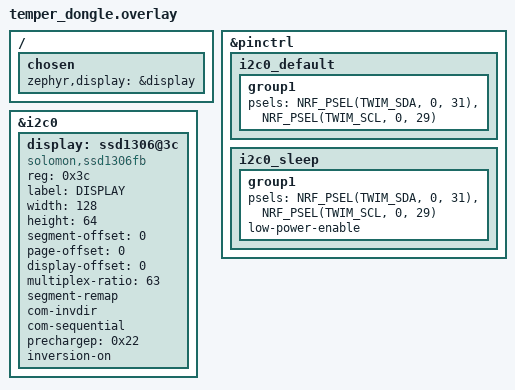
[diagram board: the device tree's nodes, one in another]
/*
 * Copyright (c) 2020 Pete Johanson
 *
 * SPDX-License-Identifier: MIT
 */

#include "temper.dtsi"

&pinctrl {
    i2c0_default: i2c0_default {
        group1 {
            psels = <NRF_PSEL(TWIM_SDA, 0, 31)>,
                    <NRF_PSEL(TWIM_SCL, 0, 29)>;
        };
    };

    i2c0_sleep: i2c0_sleep {
        group1 {
            psels = <NRF_PSEL(TWIM_SDA, 0, 31)>,
                    <NRF_PSEL(TWIM_SCL, 0, 29)>;
            low-power-enable;
        };
    };
};

&i2c0 {
    status = "okay";

    display: ssd1306@3c {
        compatible = "solomon,ssd1306fb";
        reg = <0x3c>;
        label = "DISPLAY";
        width = <128>;
        height = <64>;
        segment-offset = <0>;
        page-offset = <0>;
        display-offset = <0>;
        multiplex-ratio = <63>;
        segment-remap;
        com-invdir;
        com-sequential;
        prechargep = <0x22>;
        inversion-on;
    };
};

/ {
    chosen {
        zephyr,display = &display;
    };
};
